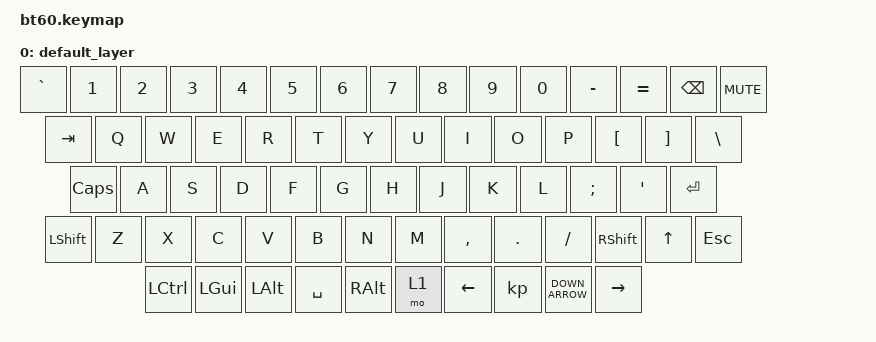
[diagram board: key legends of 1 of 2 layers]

/*
 * Copyright (c) 2020 The ZMK Contributors
 *
 * SPDX-License-Identifier: MIT
 */


/* THIS FILE WAS GENERATED!
 *
 * This file was generated automatically. You may or may not want to
 * edit it directly.
 */

#include <behaviors.dtsi>
#include <dt-bindings/zmk/keys.h>

#include <dt-bindings/zmk/bt.h>

/ {
	keymap {
		compatible = "zmk,keymap";

		default_layer {
				// ------------------------------------------------------------------------------------------
				// | ` |  1  |  2  |  3  |  4  |  5  |  6  |  7  |  8  |  9  |  0  |  -  |  =  | BKSP | MUTE  |
				// | TAB  |  Q  |  W  |  E  |  R  |  T  |  Y  |  U  |  I  |  O  |  P  |  [  |  ]  |     |     |
				// | CAPS  |  A  |  S  |  D  |  F  |  G  |  H  |  J  |  K  |  L  |  ;  |  '  |       ENTER    |
				// | SHIFT  |  Z  |  X  |  C  |  V  |  B  |  N  |  M  |  ,  |  .  | / | SHIFT |  UP   | EXTRA |
				// |  CTL  |  WIN  |  ALT  |            SPACE               | ALT | 1 | LEFT  |  DOWN | RIGHT |
				// ------------------------------------------------------------------------------------------
			bindings = <
				&kp GRAVE &kp N1 &kp N2 &kp N3 &kp N4 &kp N5 &kp N6 &kp N7 &kp  N8   &kp  N9 &kp  N0  &kp MINUS &kp EQUAL &kp BSPC &kp K_MUTE
				&kp TAB  &kp Q  &kp W  &kp E  &kp R  &kp T  &kp Y  &kp U  &kp  I    &kp  O  &kp  P   &kp LBKT &kp RBKT  &kp BSLH
				&kp CLCK  &kp A  &kp S  &kp D  &kp F  &kp G  &kp H  &kp J  &kp  K    &kp  L  &kp SEMI &kp SQT           &kp RET
				&kp LSHFT  &kp Z  &kp X  &kp C  &kp V  &kp B  &kp N  &kp M  &kp COMMA &kp DOT &kp FSLH  &kp RSHFT &kp UP_ARROW &kp ESC
				&kp LCTRL &kp LGUI &kp LALT            &kp SPACE                          &kp RALT  &mo 1 &kp LEFT_ARROW $kp DOWN_ARROW &kp RIGHT_ARROW
			>;
			sensor-bindings = <&inc_dec_kp C_VOL_UP C_VOL_DN>;
		};
		raise {
			bindings = <
				&kp ESC &kp F1 &kp F2 &kp F3 &kp F4 &kp F5 &kp F6 &kp F7 &kp  F8   &kp  F9 &kp  F10  &kp F11 &kp F12   &kp DEL &trans 
				&trans &trans &kp UP &trans &trans &trans &trans &trans &kp INS &trans &kp PSCRN &kp SLCK &kp PAUSE_BREAK &reset
				&trans    &kp LEFT &kp DOWN &kp RIGHT &trans &trans &trans &trans &trans &trans &trans &trans   &bootloader
				&kp C_PREV &kp C_VOL_DN &kp C_VOL_UP &kp C_MUTE &trans &trans &trans &trans &trans &trans &trans &kp PG_UP &trans
				&bt BT_PRV &bt BT_NXT  &trans              &trans                            &trans   &trans   &kp HOME &kp PG_DOWN &kp END
			>;
			sensor-bindings = <&inc_dec_kp C_VOL_UP C_VOL_DN>;
		};
	};
};
